# PIC32MX270F256D register map
Vendor: Microchip
Registers are 32-bit, read-write, reset 0x0 unless marked. A register's access mark holds for its fields unless they carry their own. Addresses are absolute, and some are shared; only a register's first bit layout is shown; [hi:lo] are bit positions; {n}, {i} and the like mark numbered series; 'fields as' and 'values as' point back to an identical list.

## CONFIG — Configuration words, addresses in PhysicalSpace
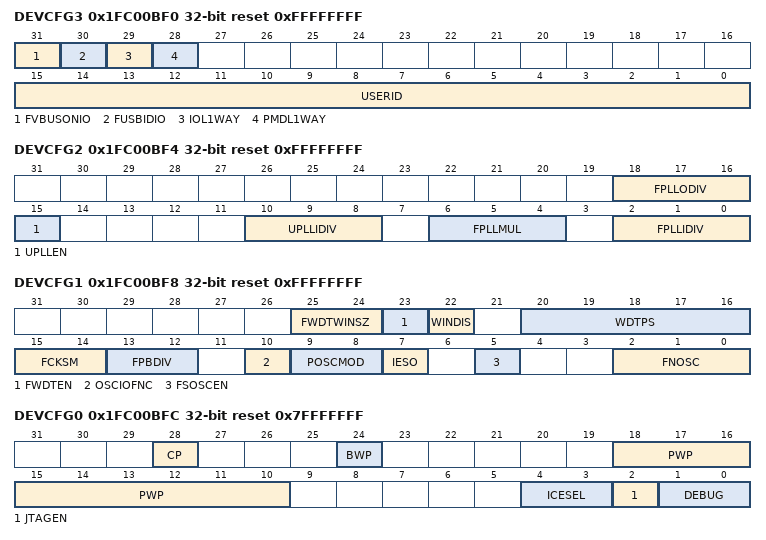
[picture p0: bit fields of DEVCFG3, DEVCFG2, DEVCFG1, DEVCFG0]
0x1FC00BF0 DEVCFG3 reset 0xFFFFFFFF
  [31] FVBUSONIO — USB VBUS ON Selection
    0=OFF (Controlled by Port Function); 1=ON (Controlled by USB Module)
  [30] FUSBIDIO — USB USID Selection
    0=OFF (Controlled by Port Function); 1=ON (Controlled by the USB Module)
  [29] IOL1WAY — Peripheral Pin Select Configuration
    1=ON (Allow only one reconfiguration); 0=OFF (Allow multiple reconfigurations)
  [28] PMDL1WAY — Peripheral Module Disable Configuration
    values as IOL1WAY
  [15:0] USERID
0x1FC00BF4 DEVCFG2 reset 0xFFFFFFFF
  [18:16] FPLLODIV — System PLL Output Clock Divider
    0=DIV_1 (PLL Divide by 1); 1=DIV_2 (PLL Divide by 2); 2=DIV_4 (PLL Divide by 4); 3=DIV_8 (PLL Divide by 8); 4=DIV_16 (PLL Divide by 16); 5=DIV_32 (PLL Divide by 32); 6=DIV_64 (PLL Divide by 64); 7=DIV_256 (PLL Divide by 256)
  [15] UPLLEN — USB PLL Enable
    0=ON (Enabled); 1=OFF (Disabled and Bypassed)
  [10:8] UPLLIDIV — USB PLL Input Divider
    {v}=DIV_{v+1} ({v+1}x Divider) (v=0..5); 6=DIV_10 (10x Divider); 7=DIV_12 (12x Divider)
  [6:4] FPLLMUL — PLL Multiplier
    {v}=MUL_{v+15} ({v+15}x Multiplier) (v=0..6); 7=MUL_24 (24x Multiplier)
  [2:0] FPLLIDIV — PLL Input Divider
    values as UPLLIDIV
0x1FC00BF8 DEVCFG1 reset 0xFFFFFFFF
  [25:24] FWDTWINSZ — Watchdog Timer Window Size
    0=WINSZ_75 (Window Size is 75%); 1=WINSZ_50 (Window Size is 50%); 2=WINSZ_37 (Window Size is 37.5%); 3=WINSZ_25 (Window Size is 25%)
  [23] FWDTEN — Watchdog Timer Enable
    0=OFF (WDT Disabled (SWDTEN Bit Controls)); 1=ON (WDT Enabled)
  [22] WINDIS — Watchdog Timer Window Enable
    0=ON (Watchdog Timer is in Window Mode); 1=OFF (Watchdog Timer is in Non-Window Mode)
  [20:16] WDTPS — Watchdog Timer Postscaler
    0=PS1 (1:1); 1=PS2 (1:2); 2=PS4 (1:4); 3=PS8 (1:8); 4=PS16 (1:16); 5=PS32 (1:32); 6=PS64 (1:64); 7=PS128 (1:128); 8=PS256 (1:256); 9=PS512 (1:512); 10=PS1024 (1:1024); 11=PS2048 (1:2048); 12=PS4096 (1:4096); 13=PS8192 (1:8192); 14=PS16384 (1:16384); 15=PS32768 (1:32768); 0b1x000=PS65536 (1:65536); 0b1x001=PS131072 (1:131072); 0b1x010=PS262144 (1:262144); 0b1x011=PS524288 (1:524288); 0b1x1xx=PS1048576 (1:1048576)
  [15:14] FCKSM — Clock Switching and Monitor Selection
    0=CSECME (Clock Switch Enable, FSCM Enabled); 1=CSECMD (Clock Switch Enable, FSCM Disabled); 3=CSDCMD (Clock Switch Disable, FSCM Disabled)
  [13:12] FPBDIV — Peripheral Clock Divisor
    0=DIV_1 (Pb_Clk is Sys_Clk/1); 1=DIV_2 (Pb_Clk is Sys_Clk/2); 2=DIV_4 (Pb_Clk is Sys_Clk/4); 3=DIV_8 (Pb_Clk is Sys_Clk/8)
  [10] OSCIOFNC — CLKO Output Signal Active on the OSCO Pin
    1=OFF (Disabled); 0=ON (Enabled)
  [9:8] POSCMOD — Primary Oscillator Configuration
    0=EC (External clock mode); 1=XT (XT osc mode); 2=HS (HS osc mode); 3=OFF (Primary osc disabled)
  [7] IESO — Internal/External Switch Over
    0=OFF (Disabled); 1=ON (Enabled)
  [5] FSOSCEN — Secondary Oscillator Enable
    0=OFF (Disabled); 1=ON (Enabled)
  [2:0] FNOSC — Oscillator Selection Bits
    0=FRC (Fast RC Osc (FRC)); 1=FRCPLL (Fast RC Osc with PLL); 2=PRI (Primary Osc (XT,HS,EC)); 3=PRIPLL (Primary Osc w/PLL (XT+,HS+,EC+PLL)); 4=SOSC (Low Power Secondary Osc (SOSC)); 5=LPRC (Low Power RC Osc (LPRC)); 6=FRCDIV16 (Fast RC Osc w/Div-by-16 (FRC/16)); 7=FRCDIV (Fast RC Osc w/Div-by-N (FRCDIV))
0x1FC00BFC DEVCFG0 reset 0x7FFFFFFF
  [28] CP — Code Protect
    0=ON (Protection Enabled); 1=OFF (Protection Disabled)
  [24] BWP — Boot Flash Write Protect bit
    0=ON (Protection Enabled); 1=OFF (Protection Disabled)
  [18:10] PWP — Program Flash Write Protect
    0x1FF=OFF (Disable); 0x1FE=PWP1K (First 1K); 0x1FD=PWP2K (First 2K); 0x1FC=PWP3K (First 3K); 0x1FB=PWP4K (First 4K); 0x1FA=PWP5K (First 5K); 0x1F9=PWP6K (First 6K); 0x1F8=PWP7K (First 7K); 0x1F7=PWP8K (First 8K); 0x1F6=PWP9K (First 9K); 0x1F5=PWP10K (First 10K); 0x1F4=PWP11K (First 11K); 0x1F3=PWP12K (First 12K); 0x1F2=PWP13K (First 13K); 0x1F1=PWP14K (First 14K); 0x1F0=PWP15K (First 15K); 0x1EF=PWP16K (First 16K); 0x1EE=PWP17K (First 17K); 0x1ED=PWP18K (First 18K); 0x1EC=PWP19K (First 19K); 0x1EB=PWP20K (First 20K); 0x1EA=PWP21K (First 21K); 0x1E9=PWP22K (First 22K); 0x1E8=PWP23K (First 23K); 0x1E7=PWP24K (First 24K); 0x1E6=PWP25K (First 25K); 0x1E5=PWP26K (First 26K); 0x1E4=PWP27K (First 27K); 0x1E3=PWP28K (First 28K); 0x1E2=PWP29K (First 29K); 0x1E1=PWP30K (First 30K); 0x1E0=PWP31K (First 31K); 0x1DF=PWP32K (First 32K); 0x1DE=PWP33K (First 33K); 0x1DD=PWP34K (First 34K); 0x1DC=PWP35K (First 35K); 0x1DB=PWP36K (First 36K); 0x1DA=PWP37K (First 37K); 0x1D9=PWP38K (First 38K); 0x1D8=PWP39K (First 39K); 0x1D7=PWP40K (First 40K); 0x1D6=PWP41K (First 41K); 0x1D5=PWP42K (First 42K); 0x1D4=PWP43K (First 43K); 0x1D3=PWP44K (First 44K); 0x1D2=PWP45K (First 45K); 0x1D1=PWP46K (First 46K); 0x1D0=PWP47K (First 47K); 0x1CF=PWP48K (First 48K); 0x1CE=PWP49K (First 49K); 0x1CD=PWP50K (First 50K); 0x1CC=PWP51K (First 51K); 0x1CB=PWP52K (First 52K); 0x1CA=PWP53K (First 53K); 0x1C9=PWP54K (First 54K); 0x1C8=PWP55K (First 55K); 0x1C7=PWP56K (First 56K); 0x1C6=PWP57K (First 57K); 0x1C5=PWP58K (First 58K); 0x1C4=PWP59K (First 59K); 0x1C3=PWP60K (First 60K); 0x1C2=PWP61K (First 61K); 0x1C1=PWP62K (First 62K); 0x1C0=PWP63K (First 63K); 0x1BF=PWP64K (First 64K); 0x1BE=PWP65K (First 65K); 0x1BD=PWP66K (First 66K); 0x1BC=PWP67K (First 67K); 0x1BB=PWP68K (First 68K); 0x1BA=PWP69K (First 69K); 0x1B9=PWP70K (First 70K); 0x1B8=PWP71K (First 71K); 0x1B7=PWP72K (First 72K); 0x1B6=PWP73K (First 73K); 0x1B5=PWP74K (First 74K); 0x1B4=PWP75K (First 75K); 0x1B3=PWP76K (First 76K); 0x1B2=PWP77K (First 77K); 0x1B1=PWP78K (First 78K); 0x1B0=PWP79K (First 79K); 0x1AF=PWP80K (First 80K); 0x1AE=PWP81K (First 81K); 0x1AD=PWP82K (First 82K); 0x1AC=PWP83K (First 83K); 0x1AB=PWP84K (First 84K); 0x1AA=PWP85K (First 85K); 0x1A9=PWP86K (First 86K); 0x1A8=PWP87K (First 87K); 0x1A7=PWP88K (First 88K); 0x1A6=PWP89K (First 89K); 0x1A5=PWP90K (First 90K); 0x1A4=PWP91K (First 91K); 0x1A3=PWP92K (First 92K); 0x1A2=PWP93K (First 93K); 0x1A1=PWP94K (First 94K); 0x1A0=PWP95K (First 95K); 0x19F=PWP96K (First 96K); 0x19E=PWP97K (First 97K); 0x19D=PWP98K (First 98K); 0x19C=PWP99K (First 99K); 0x19B=PWP100K (First 100K); 0x19A=PWP101K (First 101K); 0x199=PWP102K (First 102K); 0x198=PWP103K (First 103K); 0x197=PWP104K (First 104K); 0x196=PWP105K (First 105K); 0x195=PWP106K (First 106K); 0x194=PWP107K (First 107K); 0x193=PWP108K (First 108K); 0x192=PWP109K (First 109K); 0x191=PWP110K (First 110K); 0x190=PWP111K (First 111K); 0x18F=PWP112K (First 112K); 0x18E=PWP113K (First 113K); 0x18D=PWP114K (First 114K); 0x18C=PWP115K (First 115K); 0x18B=PWP116K (First 116K); 0x18A=PWP117K (First 117K); 0x189=PWP118K (First 118K); 0x188=PWP119K (First 119K); 0x187=PWP120K (First 120K); 0x186=PWP121K (First 121K); 0x185=PWP122K (First 122K); 0x184=PWP123K (First 123K); 0x183=PWP124K (First 124K); 0x182=PWP125K (First 125K); 0x181=PWP126K (First 126K); 0x180=PWP127K (First 127K); 0x17F=PWP128K (First 128K); 0x17E=PWP129K (First 129K); 0x17D=PWP130K (First 130K); 0x17C=PWP131K (First 131K); 0x17B=PWP132K (First 132K); 0x17A=PWP133K (First 133K); 0x179=PWP134K (First 134K); 0x178=PWP135K (First 135K); 0x177=PWP136K (First 136K); 0x176=PWP137K (First 137K); 0x175=PWP138K (First 138K); 0x174=PWP139K (First 139K); 0x173=PWP140K (First 140K); 0x172=PWP141K (First 141K); 0x171=PWP142K (First 142K); 0x170=PWP143K (First 143K); 0x16F=PWP144K (First 144K); 0x16E=PWP145K (First 145K); 0x16D=PWP146K (First 146K); 0x16C=PWP147K (First 147K); 0x16B=PWP148K (First 148K); 0x16A=PWP149K (First 149K); 0x169=PWP150K (First 150K); 0x168=PWP151K (First 151K); 0x167=PWP152K (First 152K); 0x166=PWP153K (First 153K); 0x165=PWP154K (First 154K); 0x164=PWP155K (First 155K); 0x163=PWP156K (First 156K); 0x162=PWP157K (First 157K); 0x161=PWP158K (First 158K); 0x160=PWP159K (First 159K); 0x15F=PWP160K (First 160K); 0x15E=PWP161K (First 161K); 0x15D=PWP162K (First 162K); 0x15C=PWP163K (First 163K); 0x15B=PWP164K (First 164K); 0x15A=PWP165K (First 165K); 0x159=PWP166K (First 166K); 0x158=PWP167K (First 167K); 0x157=PWP168K (First 168K); 0x156=PWP169K (First 169K); 0x155=PWP170K (First 170K); 0x154=PWP171K (First 171K); 0x153=PWP172K (First 172K); 0x152=PWP173K (First 173K); 0x151=PWP174K (First 174K); 0x150=PWP175K (First 175K); 0x14F=PWP176K (First 176K); 0x14E=PWP177K (First 177K); 0x14D=PWP178K (First 178K); 0x14C=PWP179K (First 179K); 0x14B=PWP180K (First 180K); 0x14A=PWP181K (First 181K); 0x149=PWP182K (First 182K); 0x148=PWP183K (First 183K); 0x147=PWP184K (First 184K); 0x146=PWP185K (First 185K); 0x145=PWP186K (First 186K); 0x144=PWP187K (First 187K); 0x143=PWP188K (First 188K); 0x142=PWP189K (First 189K); 0x141=PWP190K (First 190K); 0x140=PWP191K (First 191K); 0x13F=PWP192K (First 192K); 0x13E=PWP193K (First 193K); 0x13D=PWP194K (First 194K); 0x13C=PWP195K (First 195K); 0x13B=PWP196K (First 196K); 0x13A=PWP197K (First 197K); 0x139=PWP198K (First 198K); 0x138=PWP199K (First 199K); 0x137=PWP200K (First 200K); 0x136=PWP201K (First 201K); 0x135=PWP202K (First 202K); 0x134=PWP203K (First 203K); 0x133=PWP204K (First 204K); 0x132=PWP205K (First 205K); 0x131=PWP206K (First 206K); 0x130=PWP207K (First 207K); 0x12F=PWP208K (First 208K); 0x12E=PWP209K (First 209K); 0x12D=PWP210K (First 210K); 0x12C=PWP211K (First 211K); 0x12B=PWP212K (First 212K); 0x12A=PWP213K (First 213K); 0x129=PWP214K (First 214K); 0x128=PWP215K (First 215K); 0x127=PWP216K (First 216K); 0x126=PWP217K (First 217K); 0x125=PWP218K (First 218K); 0x124=PWP219K (First 219K); 0x123=PWP220K (First 220K); 0x122=PWP221K (First 221K); 0x121=PWP222K (First 222K); 0x120=PWP223K (First 223K); 0x11F=PWP224K (First 224K); 0x11E=PWP225K (First 225K); 0x11D=PWP226K (First 226K); 0x11C=PWP227K (First 227K); 0x11B=PWP228K (First 228K); 0x11A=PWP229K (First 229K); 0x119=PWP230K (First 230K); 0x118=PWP231K (First 231K); 0x117=PWP232K (First 232K); 0x116=PWP233K (First 233K); 0x115=PWP234K (First 234K); 0x114=PWP235K (First 235K); 0x113=PWP236K (First 236K); 0x112=PWP237K (First 237K); 0x111=PWP238K (First 238K); 0x110=PWP239K (First 239K); 0x10F=PWP240K (First 240K); 0x10E=PWP241K (First 241K); 0x10D=PWP242K (First 242K); 0x10C=PWP243K (First 243K); 0x10B=PWP244K (First 244K); 0x10A=PWP245K (First 245K); 0x109=PWP246K (First 246K); 0x108=PWP247K (First 247K); 0x107=PWP248K (First 248K); 0x106=PWP249K (First 249K); 0x105=PWP250K (First 250K); 0x104=PWP251K (First 251K); 0x103=PWP252K (First 252K); 0x102=PWP253K (First 253K); 0x101=PWP254K (First 254K); 0x100=PWP255K (First 255K); 255=PWP256K (First 256K)
  [4:3] ICESEL — ICE/ICD Comm Channel Select
    3=ICS_PGx1 (Communicate on PGEC1/PGED1); 2=ICS_PGx2 (Communicate on PGEC2/PGED2); 1=ICS_PGx3 (Communicate on PGEC3/PGED3); 0=ICS_PGx4 (Communicate on PGEC4/PGED4)
  [2] JTAGEN — JTAG Enable
    1=ON (JTAG Port Enabled); 0=OFF (JTAG Disabled)
  [1:0] DEBUG — Background Debugger Enable
    0=ON (Debugger is Enabled); 3=OFF (Debugger is Disabled)
